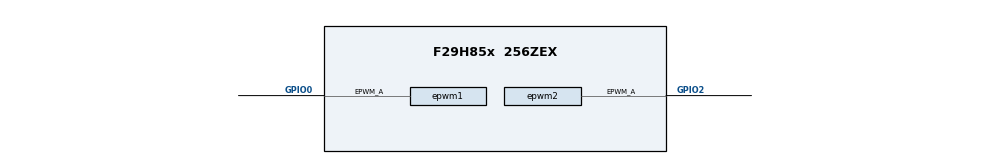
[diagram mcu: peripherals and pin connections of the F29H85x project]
/**
 * @cliArgs --device "F29H85x" --package "256ZEX" --part "F29H85x_256ZEX" --context "CPU1" --product "MCU_SDK_F29H85x@1.00.00.00"
 * @versions {"tool":"1.22.0+3877"}
 */

const divider15       = system.clockTree["PLL_REFDIV"];
divider15.divideValue = 1;

const multiplier1         = system.clockTree["PLL_IMULT"];
multiplier1.multiplyValue = 40;

const mux7       = system.clockTree["OSCCLKSRCSEL"];
mux7.inputSelect = "INTOSC2";

/**
 * Import the modules used in this configuration.
 */
const epwm  = scripting.addModule("/driverlib/epwm.js", {}, false);
const epwm1 = epwm.addInstance();
const epwm2 = epwm.addInstance();
const inputxbar_input  = scripting.addModule("/driverlib/inputxbar_input.js", {}, false);
const inputxbar_input1 = inputxbar_input.addInstance();

/**
 * Write custom configuration values to the imported modules.
 */
epwm1.$name                                                   = "myEPWM1";
epwm1.epwmTimebase_hsClockDiv                                 = "EPWM_HSCLOCK_DIVIDER_1";
epwm1.epwmTimebase_period                                     = 49;
epwm1.epwmTimebase_phaseEnable                                = true;
epwm1.epwmTimebase_syncInPulseSource                          = "EPWM_SYNC_IN_PULSE_SRC_INPUTXBAR_OUT5";
epwm1.epwmActionQualifier_EPWM_AQ_OUTPUT_A_ON_TIMEBASE_PERIOD = "EPWM_AQ_OUTPUT_LOW";
epwm1.epwmActionQualifier_EPWM_AQ_OUTPUT_A_ON_T1_COUNT_UP     = "EPWM_AQ_OUTPUT_HIGH";
epwm1.useCase                                                 = "CUSTOM";
epwm1.useInterfacePins                                        = ["EPWM#_A"];
epwm1.epwmActionQualifier_t1Source                            = "EPWM_AQ_TRIGGER_EVENT_TRIG_EPWM_SYNCIN";
epwm1.periphClock.$name                                       = "driverlib_perClock0";
epwm1.periphConfig.$name                                      = "driverlib_perConfig0";
epwm1.epwm.$assign                                            = "EPWM1";
epwm1.epwm.epwm_aPin.$assign                                  = "GPIO0";

epwm2.$name                                                    = "myEPWM2";
epwm2.epwmTimebase_hsClockDiv                                  = "EPWM_HSCLOCK_DIVIDER_1";
epwm2.epwmTimebase_period                                      = 999;
epwm2.epwmCounterCompare_cmpA                                  = 10;
epwm2.epwmActionQualifier_EPWM_AQ_OUTPUT_A_ON_TIMEBASE_ZERO    = "EPWM_AQ_OUTPUT_HIGH";
epwm2.epwmActionQualifier_EPWM_AQ_OUTPUT_A_ON_TIMEBASE_UP_CMPA = "EPWM_AQ_OUTPUT_LOW";
epwm2.useCase                                                  = "CUSTOM";
epwm2.useInterfacePins                                         = ["EPWM#_A"];
epwm2.periphClock.$name                                        = "driverlib_perClock1";
epwm2.periphConfig.$name                                       = "driverlib_perConfig1";
epwm2.epwm.$assign                                             = "EPWM2";
epwm2.epwm.epwm_aPin.$assign                                   = "GPIO2";

inputxbar_input1.$name          = "myINPUTXBARINPUT0";
inputxbar_input1.inputxbarInput = "XBAR_INPUT5";
inputxbar_input1.inputxbarGpio  = "GPIO2";
